# NUC400_v1 register map
File version: 1.0
Registers are 32-bit, read-write, reset 0x0 unless marked. A register's access mark holds for its fields unless they carry their own. Offsets are from the block's base; [hi:lo] are bit positions; {n}, {i} and the like mark numbered series; 'fields as' and 'values as' point back to an identical list.

## GPIO — GPIO Register Map
Base 0x40004000
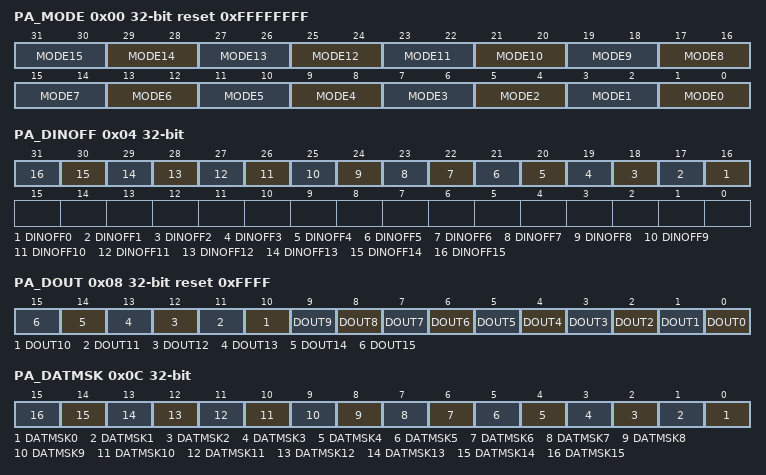
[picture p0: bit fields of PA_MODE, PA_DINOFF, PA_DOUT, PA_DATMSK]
0x00 PA_MODE reset 0xFFFFFFFF — PA I/O Mode Control
  [all] fields
    0=INPUT only mode; 1=OUTPUT mode; 2=Open-drain mode; 3=Quasi-bidirectional mode
  [2n+1:2n] MODE{n} (n=0..15) — Port N Bit M I/O Mode Control. Determine the I/O mode of port n bit m.
0x04 PA_DINOFF — PA Digital Input Path Disable Control
  [all] fields
    0=Digital input path Enabled; 1=Digital input path Disabled (Digital input is tied to low)
  [n+16] DINOFF{n} (n=0..15) — Port N Bit M Off Digital Input Path. Each of these bits is used to turn off the digital input path of port n bit m pin. If input is analog signal, users can turn off digital input path to avoid input current leakage.
0x08 PA_DOUT reset 0xFFFF — PA Data Output Value
  [all] fields
    0=Drive port n bit m high low; 1=Drive port n bit m high level
  [n] DOUT{n} (n=0..15) — Port N Bit M Output. Each of these bits control the status of port n bit m when this pin is configures as output, open-drain, or Quasi-bidirectional mode.
0x0C PA_DATMSK — PA Data Output Write Mask
  [all] fields
    0=Pn_DOUT[m] bit writing is valid; 1=Pn_DOUT[m] bit writing is ignored
  [n] DATMSK{n} (n=0..15) — Port N Bit M Data Output Write Mask. These bits are used to protect the corresponding register of Pn_DOUT[m]. When set the DATMSK [m] to 1, the writing to Pn_DOUT[m] bit is ignored. The write to port pin latch is masked.
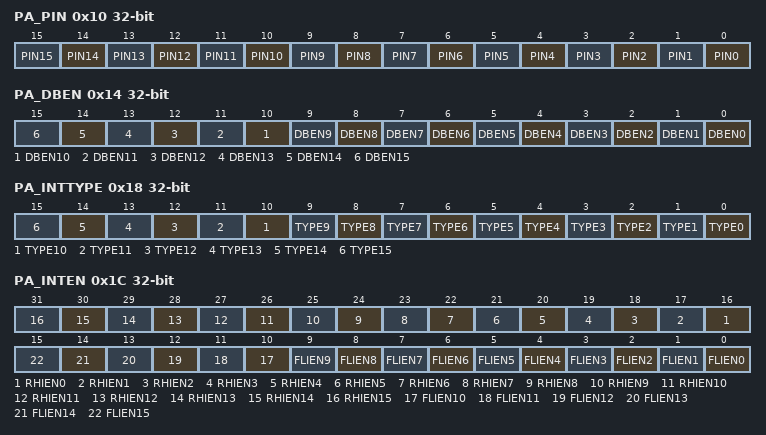
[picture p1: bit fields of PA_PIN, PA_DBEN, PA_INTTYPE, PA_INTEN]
0x10 PA_PIN ro (reset mask 0xFFFF0000) — PA Pin Value
  [n] PIN{n} (n=0..15) — Port N Bit M Pin Value. Each bit of the register reflects the actual status of the respective port pin. If bit is 1, it indicates the corresponding pin status is high, else the pin status is low.
0x14 PA_DBEN — PA De-bounce Enable Control
  [all] fields
    0=Port n bit m input de-bounce Disabled; 1=Port n bit m input de-bounce Enabled
  [n] DBEN{n} (n=0..15) — Port N Bit M Input De-Bounce Enable. DBEN[m] is used to enable the de-bounce function for each corresponding bit. DBEN[m] is valid for "edge-triggered" interrupt only and is ignored for "level triggered" interrupt. If the input signal pulse width can't be sampled by continuous two de-bounce sample cycle The input signal transition is seen as the signal bounce and will not trigger the interrupt. The de-bounce clock is controlled by GPIO_DBCTL register.
0x18 PA_INTTYPE — PA Interrupt Trigger Type Register
  [all] fields
    0=Edge triggered interrupt; 1=Level triggered interrupt
  [n] TYPE{n} (n=0..15) — Port N Bit M Edge Or Level Triggered Interrupt Control. TYPE[m] decides the pin interrupt triggered by level or edge. If the interrupt is by edge trigger, the trigger source can be controlled by de-bounce. If the interrupt is by level trigger, the input source is sampled by one HCLK clock and generates the interrupt. Note1: If pin is set as the level trigger interrupt, only one level can be set on the registers Pn_INTEN. If set both the level to trigger interrupt, the setting is ignored and no interrupt will occur. Note2: The de-bounce function is valid for edge triggered interrupt. If the interrupt mode is level triggered, the de-bounce enable bit is ignored.
0x1C PA_INTEN — PA Interrupt Enable
  [n+16] RHIEN{n} (n=0..15) — Port N Bit M Interrupt Enable For Rising Edge Or High Level Input. RHIEN[m] enables the interrupt for each of the corresponding input of Port n. Setting this bit to 1 also enables the pin wake-up function.
    0=Port n bit m high-level or rising edge interrupt Disabled; 1=Port n bit m high-level or rising edge interrupt Enabled
  [n] FLIEN{n} (n=0..15) — Port N Bit M Interrupt Enable For Falling Edge Or Low Level Input. FLIEN[n] enables the interrupt for each of the corresponding input of Port n. Setting this bit to 1 also enables the pin wake-up function.
    0=Port n bit m low-level or falling edge interrupt Disabled; 1=Port n bit m low-level or falling edge interrupt Enabled
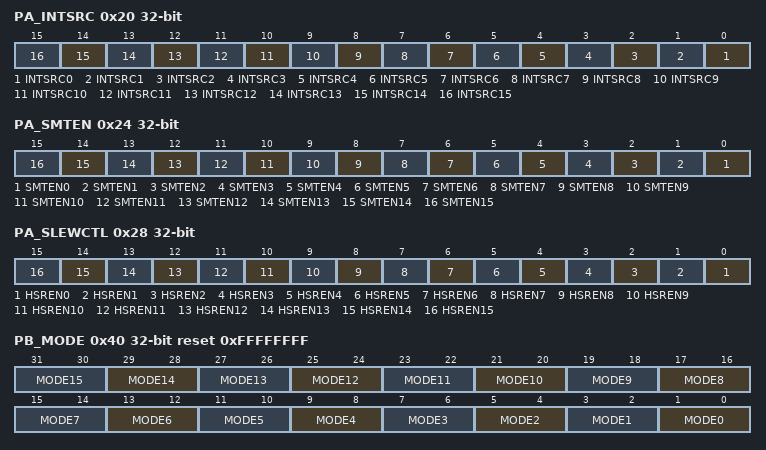
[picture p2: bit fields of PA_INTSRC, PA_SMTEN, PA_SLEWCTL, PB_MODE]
0x20 PA_INTSRC (reset mask 0xFFFF0000) — PA Interrupt Source Flag
  [all] fields
    0=No interrupt at Port n. No effect; 1=Port n bit m generate an interrupt. Clear the correspond pending interrupt
  [n] INTSRC{n} (n=0..15) — Port N Bit M Interrupt Trigger Source Indicator. Read:
0x24 PA_SMTEN — PA Input Schmitt Trigger Enable
  [all] fields
    0=P I/O input Schmitt Trigger function Disabled; 1=P I/O input Schmitt Trigger function Enabled
  [n] SMTEN{n} (n=0..15) — Port N Bit M Input Schmitt Trigger Enable Bit
0x28 PA_SLEWCTL — PA High Slew Rate Control
  [all] fields
    0=P I/O output with basic slew rate; 1=P I/O output with higher slew rate
  [n] HSREN{n} (n=0..15) — Port N Bit M High Slew Rate Control
0x40 PB_MODE reset 0xFFFFFFFF — PB I/O Mode Control
  fields as PA_MODE
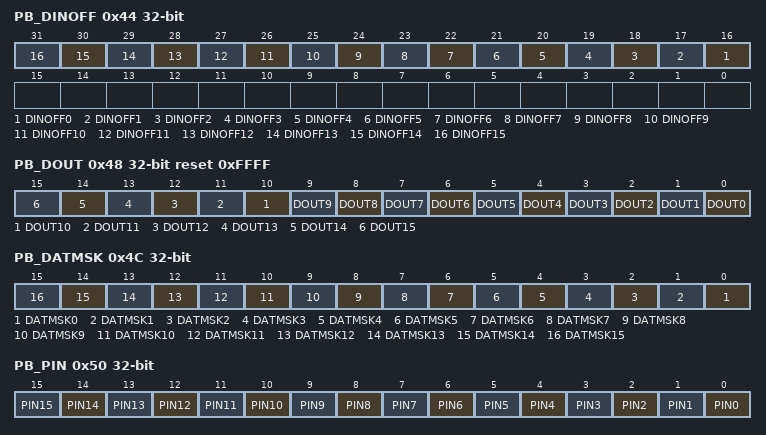
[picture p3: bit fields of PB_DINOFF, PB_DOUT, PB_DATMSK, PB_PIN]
0x44 PB_DINOFF — PB Digital Input Path Disable Control
  fields as PA_DINOFF
0x48 PB_DOUT reset 0xFFFF — PB Data Output Value
  fields as PA_DOUT
0x4C PB_DATMSK — PB Data Output Write Mask
  fields as PA_DATMSK
0x50 PB_PIN ro (reset mask 0xFFFF0000) — PB Pin Value
  fields as PA_PIN
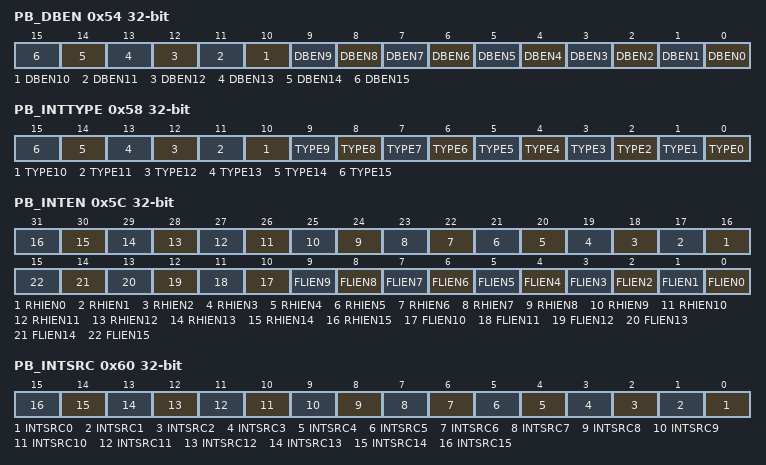
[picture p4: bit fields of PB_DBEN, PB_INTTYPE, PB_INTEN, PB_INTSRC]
0x54 PB_DBEN — PB De-bounce Enable Control
  fields as PA_DBEN
0x58 PB_INTTYPE — PB Interrupt Trigger Type Register
  fields as PA_INTTYPE
0x5C PB_INTEN — PB Interrupt Enable
  fields as PA_INTEN
0x60 PB_INTSRC (reset mask 0xFFFF0000) — PB Interrupt Source Flag
  fields as PA_INTSRC
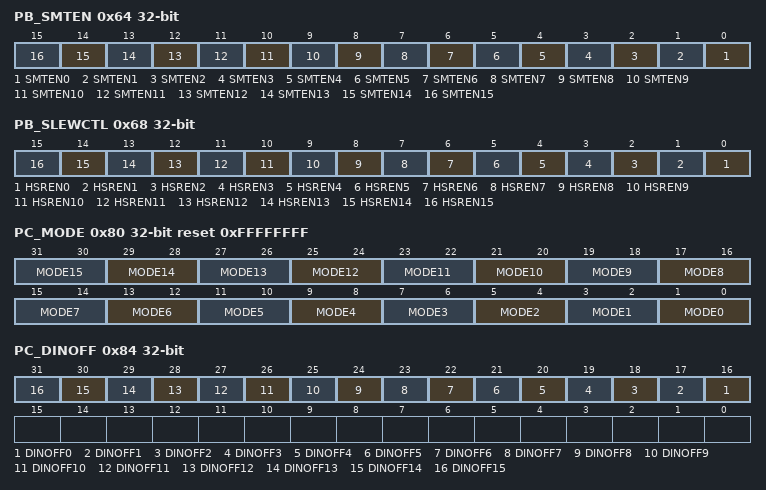
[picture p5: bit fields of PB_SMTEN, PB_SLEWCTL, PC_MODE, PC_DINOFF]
0x64 PB_SMTEN — PB Input Schmitt Trigger Enable
  fields as PA_SMTEN
0x68 PB_SLEWCTL — PB High Slew Rate Control
  fields as PA_SLEWCTL
0x80 PC_MODE reset 0xFFFFFFFF — PC I/O Mode Control
  fields as PA_MODE
0x84 PC_DINOFF — PC Digital Input Path Disable Control
  fields as PA_DINOFF
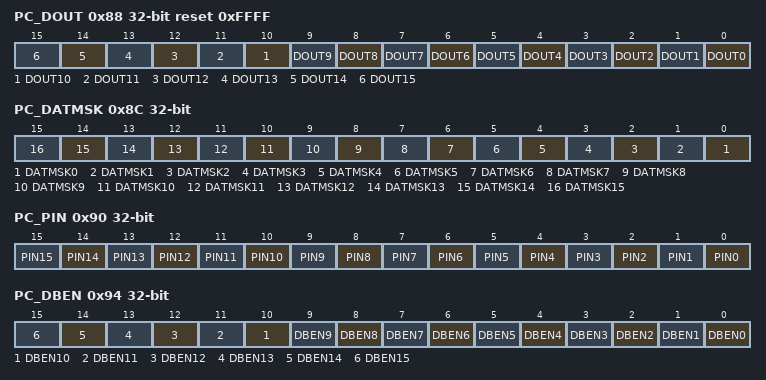
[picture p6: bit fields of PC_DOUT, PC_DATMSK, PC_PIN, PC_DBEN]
0x88 PC_DOUT reset 0xFFFF — PC Data Output Value
  fields as PA_DOUT
0x8C PC_DATMSK — PC Data Output Write Mask
  fields as PA_DATMSK
0x90 PC_PIN ro (reset mask 0xFFFF0000) — PC Pin Value
  fields as PA_PIN
0x94 PC_DBEN — PC De-bounce Enable Control
  fields as PA_DBEN
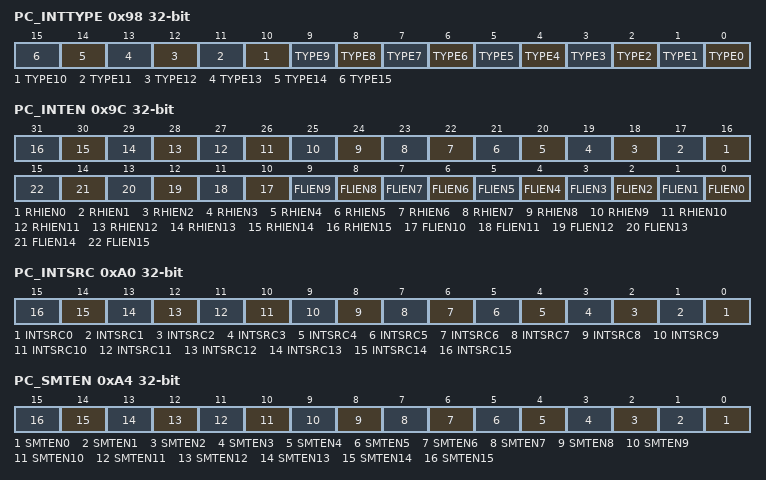
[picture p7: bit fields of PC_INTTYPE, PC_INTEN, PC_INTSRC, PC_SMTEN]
0x98 PC_INTTYPE — PC Interrupt Trigger Type Register
  fields as PA_INTTYPE
0x9C PC_INTEN — PC Interrupt Enable
  fields as PA_INTEN
0xA0 PC_INTSRC (reset mask 0xFFFF0000) — PC Interrupt Source Flag
  fields as PA_INTSRC
0xA4 PC_SMTEN — PC Input Schmitt Trigger Enable
  fields as PA_SMTEN
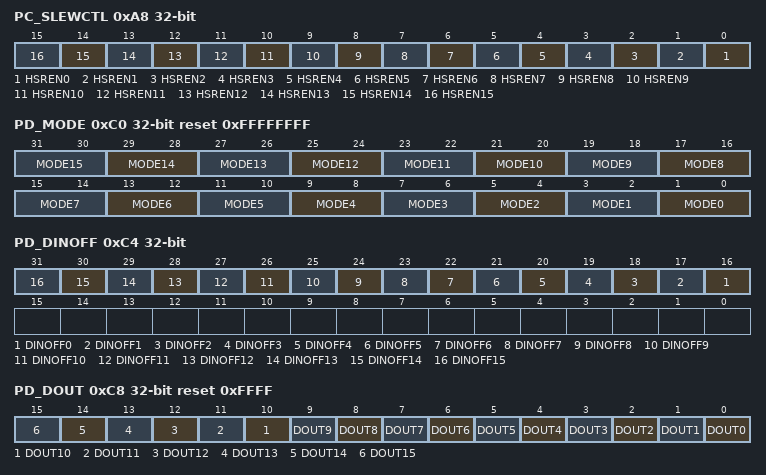
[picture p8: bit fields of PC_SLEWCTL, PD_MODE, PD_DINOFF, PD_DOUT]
0xA8 PC_SLEWCTL — PC High Slew Rate Control
  fields as PA_SLEWCTL
0xC0 PD_MODE reset 0xFFFFFFFF — PD I/O Mode Control
  fields as PA_MODE
0xC4 PD_DINOFF — PD Digital Input Path Disable Control
  fields as PA_DINOFF
0xC8 PD_DOUT reset 0xFFFF — PD Data Output Value
  fields as PA_DOUT
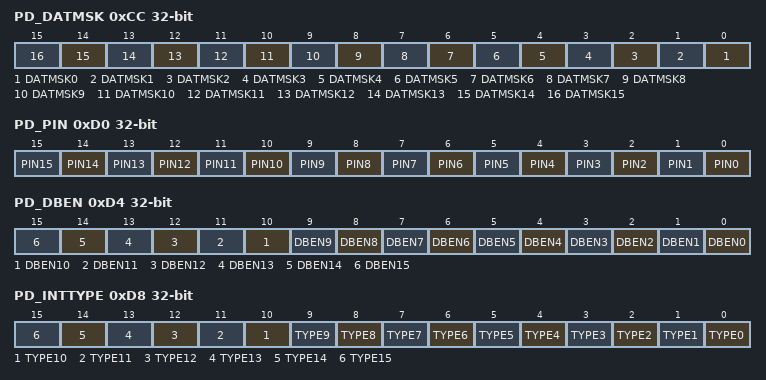
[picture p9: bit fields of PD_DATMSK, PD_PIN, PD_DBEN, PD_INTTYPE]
0xCC PD_DATMSK — PD Data Output Write Mask
  fields as PA_DATMSK
0xD0 PD_PIN ro (reset mask 0xFFFF0000) — PD Pin Value
  fields as PA_PIN
0xD4 PD_DBEN — PD De-bounce Enable Control
  fields as PA_DBEN
0xD8 PD_INTTYPE — PD Interrupt Trigger Type Register
  fields as PA_INTTYPE
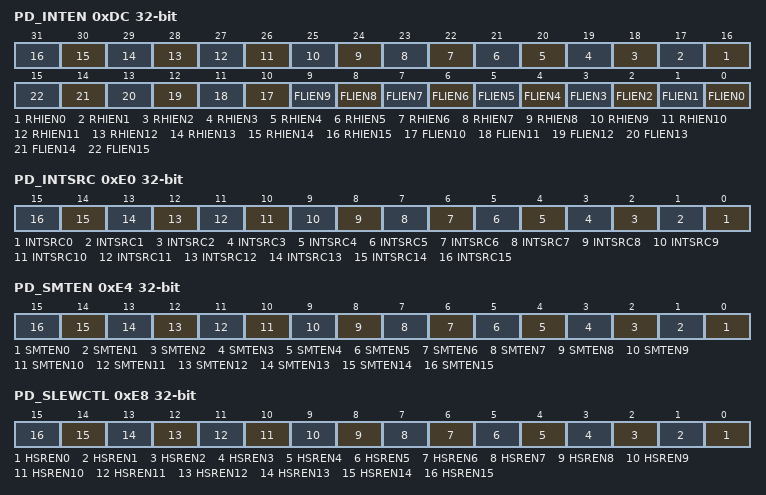
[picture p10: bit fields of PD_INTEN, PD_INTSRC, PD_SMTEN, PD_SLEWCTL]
0xDC PD_INTEN — PD Interrupt Enable
  fields as PA_INTEN
0xE0 PD_INTSRC (reset mask 0xFFFF0000) — PD Interrupt Source Flag
  fields as PA_INTSRC
0xE4 PD_SMTEN — PD Input Schmitt Trigger Enable
  fields as PA_SMTEN
0xE8 PD_SLEWCTL — PD High Slew Rate Control
  fields as PA_SLEWCTL
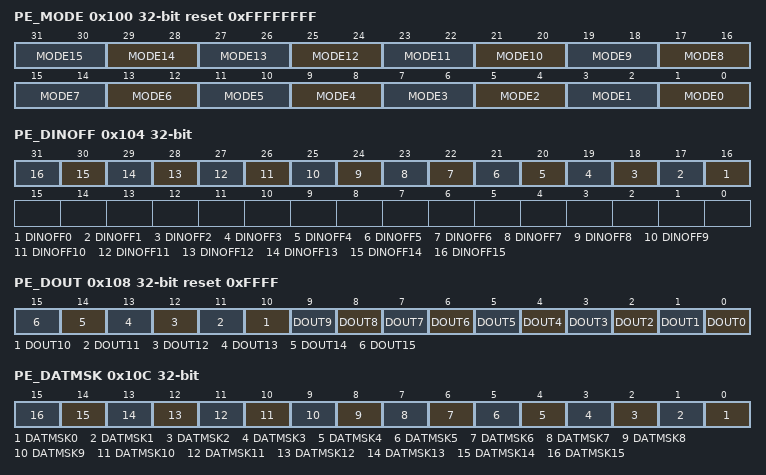
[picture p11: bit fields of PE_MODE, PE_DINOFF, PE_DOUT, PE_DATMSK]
0x100 PE_MODE reset 0xFFFFFFFF — PE I/O Mode Control
  fields as PA_MODE
0x104 PE_DINOFF — PE Digital Input Path Disable Control
  fields as PA_DINOFF
0x108 PE_DOUT reset 0xFFFF — PE Data Output Value
  fields as PA_DOUT
0x10C PE_DATMSK — PE Data Output Write Mask
  fields as PA_DATMSK
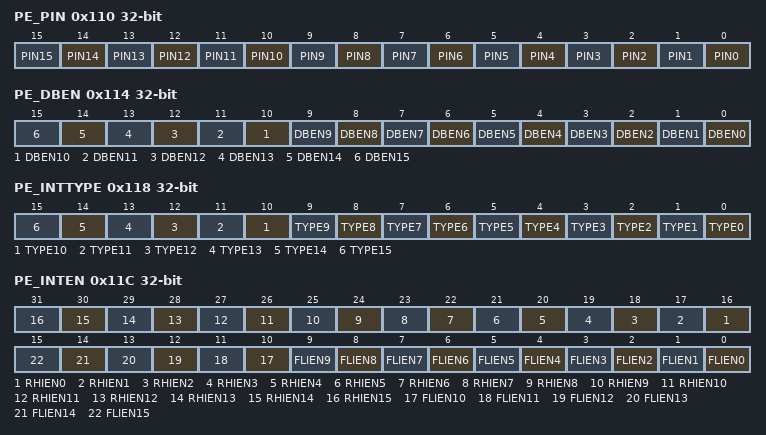
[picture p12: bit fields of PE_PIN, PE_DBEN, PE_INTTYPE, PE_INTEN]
0x110 PE_PIN ro (reset mask 0xFFFF0000) — PE Pin Value
  fields as PA_PIN
0x114 PE_DBEN — PE De-bounce Enable Control
  fields as PA_DBEN
0x118 PE_INTTYPE — PE Interrupt Trigger Type Register
  fields as PA_INTTYPE
0x11C PE_INTEN — PE Interrupt Enable
  fields as PA_INTEN
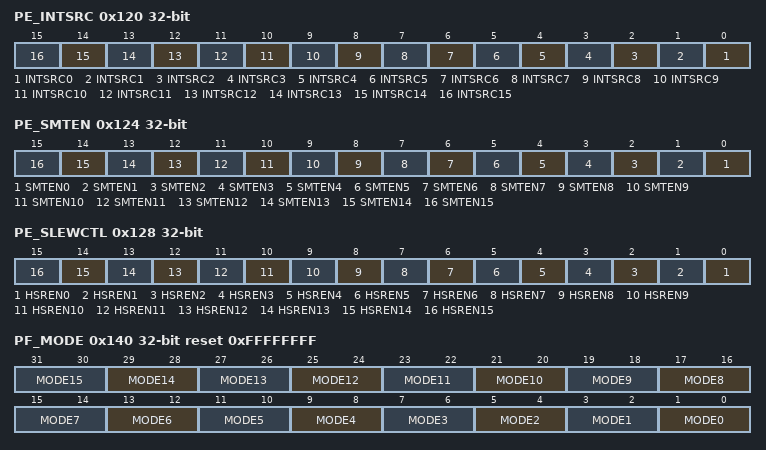
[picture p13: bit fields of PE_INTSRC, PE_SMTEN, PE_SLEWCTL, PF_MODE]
0x120 PE_INTSRC (reset mask 0xFFFF0000) — PE Interrupt Source Flag
  fields as PA_INTSRC
0x124 PE_SMTEN — PE Input Schmitt Trigger Enable
  fields as PA_SMTEN
0x128 PE_SLEWCTL — PE High Slew Rate Control
  fields as PA_SLEWCTL
0x140 PF_MODE reset 0xFFFFFFFF — PF I/O Mode Control
  fields as PA_MODE
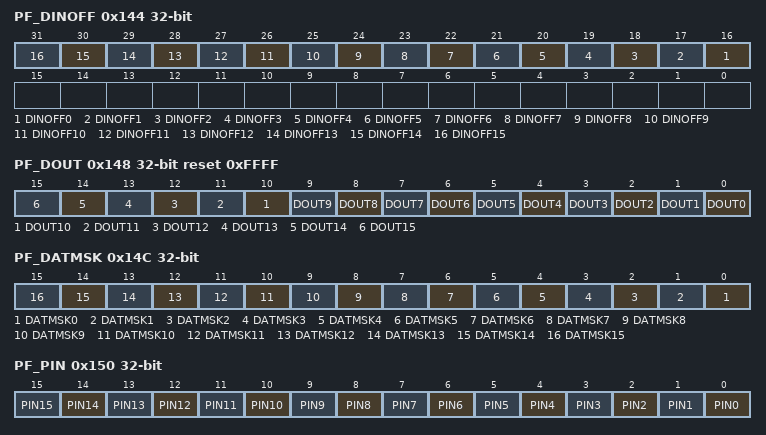
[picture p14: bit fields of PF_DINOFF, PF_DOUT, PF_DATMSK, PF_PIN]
0x144 PF_DINOFF — PF Digital Input Path Disable Control
  fields as PA_DINOFF
0x148 PF_DOUT reset 0xFFFF — PF Data Output Value
  fields as PA_DOUT
0x14C PF_DATMSK — PF Data Output Write Mask
  fields as PA_DATMSK
0x150 PF_PIN ro (reset mask 0xFFFF0000) — PF Pin Value
  fields as PA_PIN
0x154 PF_DBEN — PF De-bounce Enable Control
  fields as PA_DBEN
0x158 PF_INTTYPE — PF Interrupt Trigger Type Register
  fields as PA_INTTYPE
0x15C PF_INTEN — PF Interrupt Enable
  fields as PA_INTEN
0x160 PF_INTSRC (reset mask 0xFFFF0000) — PF Interrupt Source Flag
  fields as PA_INTSRC
0x164 PF_SMTEN — PF Input Schmitt Trigger Enable
  fields as PA_SMTEN
0x168 PF_SLEWCTL — PF High Slew Rate Control
  fields as PA_SLEWCTL
0x180 PG_MODE reset 0xFFFFFFFF — PG I/O Mode Control
  fields as PA_MODE
0x184 PG_DINOFF — PG Digital Input Path Disable Control
  fields as PA_DINOFF
0x188 PG_DOUT reset 0xFFFF — PG Data Output Value
  fields as PA_DOUT
0x18C PG_DATMSK — PG Data Output Write Mask
  fields as PA_DATMSK
0x190 PG_PIN ro (reset mask 0xFFFF0000) — PG Pin Value
  fields as PA_PIN
0x194 PG_DBEN — PG De-bounce Enable Control
  fields as PA_DBEN
0x198 PG_INTTYPE — PG Interrupt Trigger Type Register
  fields as PA_INTTYPE
0x19C PG_INTEN — PG Interrupt Enable
  fields as PA_INTEN
0x1A0 PG_INTSRC (reset mask 0xFFFF0000) — PG Interrupt Source Flag
  fields as PA_INTSRC
0x1A4 PG_SMTEN — PG Input Schmitt Trigger Enable
  fields as PA_SMTEN
0x1A8 PG_SLEWCTL — PG High Slew Rate Control
  fields as PA_SLEWCTL
0x1C0 PH_MODE reset 0xFFFFFFFF — PH I/O Mode Control
  fields as PA_MODE
0x1C4 PH_DINOFF — PH Digital Input Path Disable Control
  fields as PA_DINOFF
0x1C8 PH_DOUT reset 0xFFFF — PH Data Output Value
  fields as PA_DOUT
0x1CC PH_DATMSK — PH Data Output Write Mask
  fields as PA_DATMSK
0x1D0 PH_PIN ro (reset mask 0xFFFF0000) — PH Pin Value
  fields as PA_PIN
0x1D4 PH_DBEN — PH De-bounce Enable Control
  fields as PA_DBEN
0x1D8 PH_INTTYPE — PH Interrupt Trigger Type Register
  fields as PA_INTTYPE
0x1DC PH_INTEN — PH Interrupt Enable
  fields as PA_INTEN
0x1E0 PH_INTSRC (reset mask 0xFFFF0000) — PH Interrupt Source Flag
  fields as PA_INTSRC
0x1E4 PH_SMTEN — PH Input Schmitt Trigger Enable
  fields as PA_SMTEN
0x1E8 PH_SLEWCTL — PH High Slew Rate Control
  fields as PA_SLEWCTL
0x200 PI_MODE reset 0xFFFFFFFF — PI I/O Mode Control
  fields as PA_MODE
0x204 PI_DINOFF — PI Digital Input Path Disable Control
  fields as PA_DINOFF
0x208 PI_DOUT reset 0xFFFF — PI Data Output Value
  fields as PA_DOUT
0x20C PI_DATMSK — PI Data Output Write Mask
  fields as PA_DATMSK
0x210 PI_PIN ro (reset mask 0xFFFF0000) — PI Pin Value
  fields as PA_PIN
0x214 PI_DBEN — PI De-bounce Enable Control
  fields as PA_DBEN
0x218 PI_INTTYPE — PI Interrupt Trigger Type Register
  fields as PA_INTTYPE
0x21C PI_INTEN — PI Interrupt Enable
  fields as PA_INTEN
0x220 PI_INTSRC (reset mask 0xFFFF0000) — PI Interrupt Source Flag
  fields as PA_INTSRC
0x224 PI_SMTEN — PI Input Schmitt Trigger Enable
  fields as PA_SMTEN
0x228 PI_SLEWCTL — PI High Slew Rate Control
  fields as PA_SLEWCTL
0x440 GPIO_DBCTL reset 0x20 — Interrupt De-bounce Control
  [5] ICLKON — Interrupt Clock On Mode. Setting this bit to 0 will disable the interrupt generate circuit clock if the pin[n] interrupt is disabled.
    0=Disable the clock if the all port interrupts are disabled; 1=Interrupt generated circuit clock always Enabled
  [4] DBCLKSRC — De-Bounce Counter Clock Source Selection
    0=De-bounce counter clock source is the HCLK; 1=De-bounce counter clock source is the internal 10 kHz clock
  [3:0] DBCLKSEL — De-Bounce Sampling Cycle Selection
    0=Sample interrupt input once per 1 clocks; 1=Sample interrupt input once per 2 clocks; 2=Sample interrupt input once per 4 clocks; 3=Sample interrupt input once per 8 clocks; 4=Sample interrupt input once per 16 clocks; 5=Sample interrupt input once per 32 clocks; 6=Sample interrupt input once per 64 clocks; 7=Sample interrupt input once per 128 clocks; 8=Sample interrupt input once per 256 clocks; 9=Sample interrupt input once per 2*256 clocks; 10=Sample interrupt input once per 4*256 clocks; 11=Sample interrupt input once per 8*256 clocks; 12=Sample interrupt input once per 16*256 clocks; 13=Sample interrupt input once per 32*256 clocks; 14=Sample interrupt input once per 64*256 clocks; 15=Sample interrupt input once per 128*256 clocks
{0x800+4i} PA{i}_PDIO reset 0x1 (i=0..15) — GPIO PA.n Pin Data Input/Output
  [0] PDIO — Port N Bit M (PDIO) Value. Write: For example, a writing of PA0 reflects the value of bit PA_DOUT[0], a reading returns the value of PA_PIN[0].
    0=Clear PDIO port latch to output low. Port pin of PDIO is a low level; 1=Set PDIO port latch to output high. Port pin of PDIO is a high level
{0x840+4i} PB{i}_PDIO reset 0x1 (i=0..15) — GPIO PB.n Pin Data Input/Output
  fields as PA0_PDIO
{0x880+4i} PC{i}_PDIO reset 0x1 (i=0..15) — GPIO PC.n Pin Data Input/Output
  fields as PA0_PDIO
{0x8C0+4i} PD{i}_PDIO reset 0x1 (i=0..15) — GPIO PD.n Pin Data Input/Output
  fields as PA0_PDIO
{0x900+4i} PE{i}_PDIO reset 0x1 (i=0..15) — GPIO PE.n Pin Data Input/Output
  fields as PA0_PDIO
{0x940+4i} PF{i}_PDIO reset 0x1 (i=0..15) — GPIO PF.n Pin Data Input/Output
  fields as PA0_PDIO
{0x980+4i} PG{i}_PDIO reset 0x1 (i=0..15) — GPIO PG.n Pin Data Input/Output
  fields as PA0_PDIO
{0x9C0+4i} PH{i}_PDIO reset 0x1 (i=0..15) — GPIO PH.n Pin Data Input/Output
  fields as PA0_PDIO
{0xA00+4i} PI{i}_PDIO reset 0x1 (i=0..15) — GPIO PI.n Pin Data Input/Output
  fields as PA0_PDIO
